# TMS320F280049 register map
Vendor: Texas Instruments; Series: C2000 F28004x; File version: 0.2.0-generated
Registers are 16-bit, read-write, reset 0x0 unless marked. A register's access mark holds for its fields unless they carry their own. Offsets are from the block's base; [hi:lo] are bit positions; {n}, {i} and the like mark numbered series.

## DEVCFGREGS — DEV CFG Registers
Base 0x000BA000
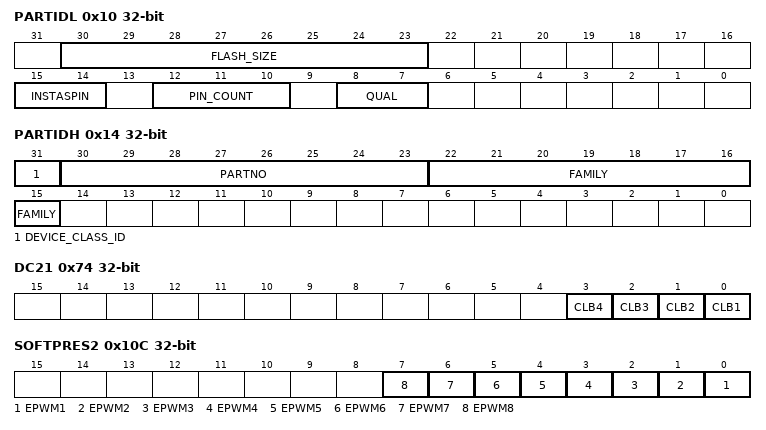
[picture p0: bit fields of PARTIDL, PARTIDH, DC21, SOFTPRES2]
0x10 PARTIDL 32-bit — Lower 32-bit of Device PART Identification Number
  [30:23] FLASH_SIZE — Flash size in KB
  [15:14] INSTASPIN — Instaspin feature set
  [12:10] PIN_COUNT — Device Pin Count
  [8:7] QUAL — Qualification Status
0x14 PARTIDH 32-bit — Upper 32-bit of Device PART Identification Number
  [31] DEVICE_CLASS_ID
  [30:23] PARTNO — Device part number
  [22:15] FAMILY — Device family
0x18 REVID 32-bit — Device Revision Number
  [30:15] REVID — Device Revision ID. This is specific to the Device
0x74 DC21 32-bit — Device Capability: CLB
  [n-1] CLB{n} (n=1..4) — CLB{n} Present
0xE8 FUSEERR 32-bit — e-Fuse error Status register
  [5] ERR — Efuse Self Test Error Status
  [8:4] ALERR — Efuse Autoload Error Status
0x104 SOFTPRES0 32-bit — Processing Block Software Reset register
  [0] CPU1_CLA1 — CPU1_CLA1 software reset bit
0x10C SOFTPRES2 32-bit — Peripheral Software Reset register
  [n-1] EPWM{n} (n=1..8) — EPWM{n} software reset bit
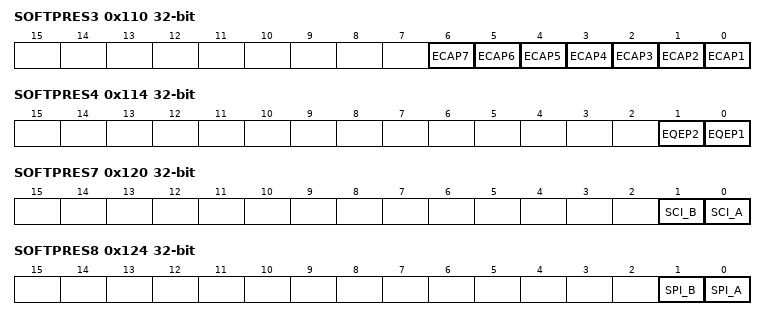
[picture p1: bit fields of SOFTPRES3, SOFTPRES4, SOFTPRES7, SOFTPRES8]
0x110 SOFTPRES3 32-bit — Peripheral Software Reset register
  [n-1] ECAP{n} (n=1..7) — ECAP{n} software reset bit
0x114 SOFTPRES4 32-bit — Peripheral Software Reset register
  [1] EQEP2 — EQEP2 software reset bit
  [0] EQEP1 — EQEP1 software reset bit
0x11C SOFTPRES6 32-bit — Peripheral Software Reset register
  [0] SD1 — SD1 software reset bit
0x120 SOFTPRES7 32-bit — Peripheral Software Reset register
  [1] SCI_B — SCI_B software reset bit
  [0] SCI_A — SCI_A software reset bit
0x124 SOFTPRES8 32-bit — Peripheral Software Reset register
  [1] SPI_B — SPI_B software reset bit
  [0] SPI_A — SPI_A software reset bit
0x128 SOFTPRES9 32-bit — Peripheral Software Reset register
  [0] I2C_A — I2C_A software reset bit
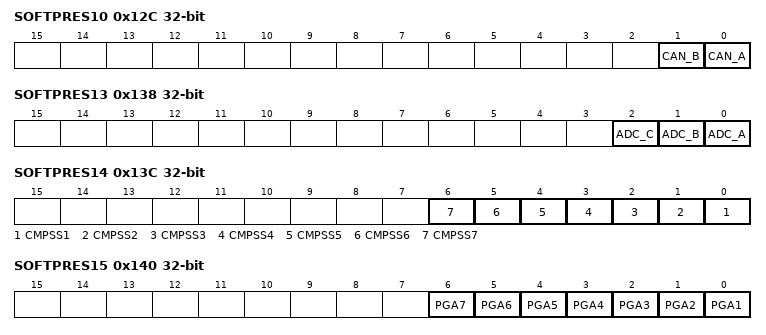
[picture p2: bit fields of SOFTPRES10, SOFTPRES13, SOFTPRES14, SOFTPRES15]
0x12C SOFTPRES10 32-bit — Peripheral Software Reset register
  [1] CAN_B — CAN_B software reset bit
  [0] CAN_A — CAN_A software reset bit
0x138 SOFTPRES13 32-bit — Peripheral Software Reset register
  [2] ADC_C — ADC_C software reset bit
  [1] ADC_B — ADC_B software reset bit
  [0] ADC_A — ADC_A software reset bit
0x13C SOFTPRES14 32-bit — Peripheral Software Reset register
  [n-1] CMPSS{n} (n=1..7) — CMPSS{n} software reset bit
0x140 SOFTPRES15 32-bit — Peripheral Software Reset register
  [n-1] PGA{n} (n=1..7) — PGA{n} software reset bit
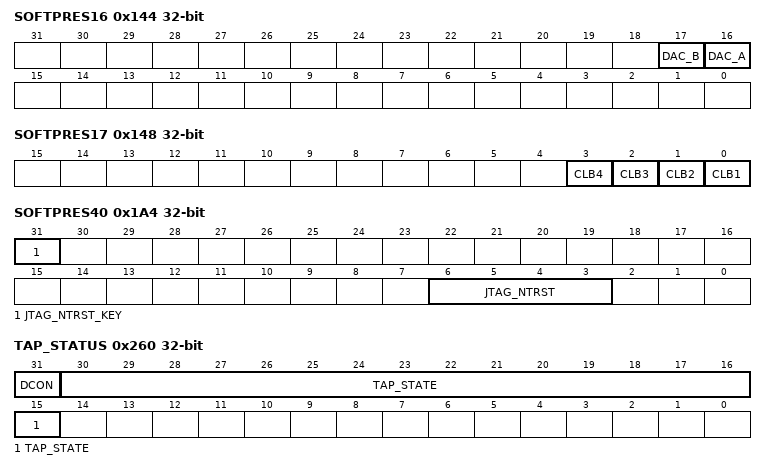
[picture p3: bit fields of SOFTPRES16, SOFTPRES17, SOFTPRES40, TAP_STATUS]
0x144 SOFTPRES16 32-bit — Peripheral Software Reset register
  [17] DAC_B — Buffered_DAC_B software reset bit
  [16] DAC_A — Buffered_DAC_A software reset bit
0x148 SOFTPRES17 32-bit — Peripheral Software Reset register
  [n-1] CLB{n} (n=1..4) — CLB{n} software reset bit
0x14C SOFTPRES18 32-bit — Peripheral Software Reset register
0x150 SOFTPRES19 32-bit — Peripheral Software Reset register
  [0] LIN_A — LIN_A software reset bit
0x154 SOFTPRES20 32-bit — Peripheral Software Reset register
  [0] PMBUS_A — PMBUS_A software reset bit
0x158 SOFTPRES21 32-bit — Peripheral Software Reset register
0x1A4 SOFTPRES40 32-bit — Peripheral Software Reset register
  [31] JTAG_NTRST_KEY
  [6:3] JTAG_NTRST — Multi Bit JTAG nTRST
0x260 TAP_STATUS 32-bit — Status of JTAG State machine and Debugger Connect
  [31] DCON — Debugger Connect Indication
  [30:15] TAP_STATE — Present JTAG TAP State

## CLKCFGREGS — CLK CFG Registers
Base 0x000BA400
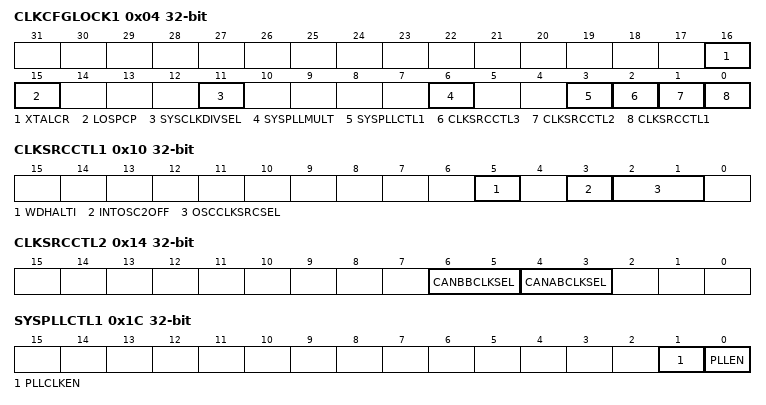
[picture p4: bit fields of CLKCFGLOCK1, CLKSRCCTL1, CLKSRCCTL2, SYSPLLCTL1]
0x04 CLKCFGLOCK1 32-bit — Lock bit for CLKCFG registers
  [16] XTALCR — Lock bit for XTALCR register
  [15] LOSPCP — Lock bit for LOSPCP register
  [11] SYSCLKDIVSEL — Lock bit for SYSCLKDIVSEL register
  [6] SYSPLLMULT — Lock bit for SYSPLLMULT register
  [3] SYSPLLCTL1 — Lock bit for SYSPLLCTL1 register
  [2] CLKSRCCTL3 — Lock bit for CLKSRCCTL3 register
  [1] CLKSRCCTL2 — Lock bit for CLKSRCCTL2 register
  [0] CLKSRCCTL1 — Lock bit for CLKSRCCTL1 register
0x10 CLKSRCCTL1 32-bit — Clock Source Control register-1
  [5] WDHALTI — Watchdog HALT Mode Ignore Bit
  [3] INTOSC2OFF — Internal Oscillator 2 Off Bit
  [2:1] OSCCLKSRCSEL — OSCCLK Source Select Bit
0x14 CLKSRCCTL2 32-bit — Clock Source Control register-2
  [6:5] CANBBCLKSEL — CANB Bit Clock Source Select Bit
  [4:3] CANABCLKSEL — CANA Bit Clock Source Select Bit
0x18 CLKSRCCTL3 32-bit — Clock Source Control register-3
  [4:2] XCLKOUTSEL — XCLKOUT Source Select Bit
0x1C SYSPLLCTL1 32-bit — SYSPLL Control register-1
  [1] PLLCLKEN — SYSPLL bypassed or included in the PLLSYSCLK path
  [0] PLLEN — SYSPLL enable/disable bit
0x28 SYSPLLMULT 32-bit — SYSPLL Multiplier register
  [20:18] ODIV — Output Clock Divider
  [10:9] FMULT — SYSPLL Fractional Multiplier
  [12:6] IMULT — SYSPLL Integer Multiplier
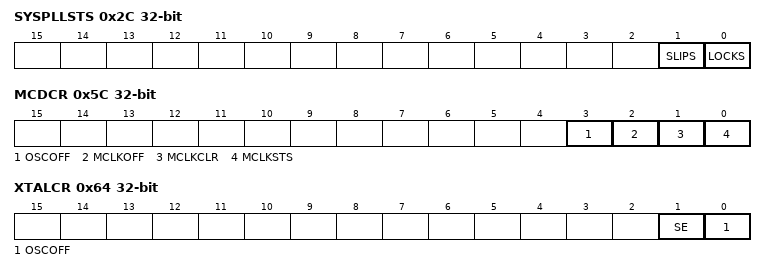
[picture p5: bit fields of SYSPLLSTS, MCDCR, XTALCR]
0x2C SYSPLLSTS 32-bit — SYSPLL Status register
  [1] SLIPS — SYSPLL Slip Status Bit
  [0] LOCKS — SYSPLL Lock Status Bit
0x44 SYSCLKDIVSEL 32-bit — System Clock Divider Select register
  [10:5] PLLSYSCLKDIV — PLLSYSCLK Divide Select
0x50 XCLKOUTDIVSEL 32-bit — XCLKOUT Divider Select register
  [2:1] XCLKOUTDIV — XCLKOUT Divide Select
0x58 LOSPCP 32-bit — Low Speed Clock Source Prescalar
  [4:2] LSPCLKDIV — LSPCLK Divide Select
0x5C MCDCR 32-bit — Missing Clock Detect Control Register
  [3] OSCOFF — Oscillator Clock Off Bit
  [2] MCLKOFF — Missing Clock Detect Off Bit
  [1] MCLKCLR — Missing Clock Clear Bit
  [0] MCLKSTS — Missing Clock Status Bit
0x60 X1CNT 32-bit — 10-bit Counter on X1 Clock
  [16] CLR — X1 Counter Clear
  [18:9] X1CNT — X1 Counter
0x64 XTALCR 32-bit — XTAL Control Register
  [1] SE — XTAL Oscilator in Single-Ended mode
  [0] OSCOFF — XTAL Oscillator powered-down
